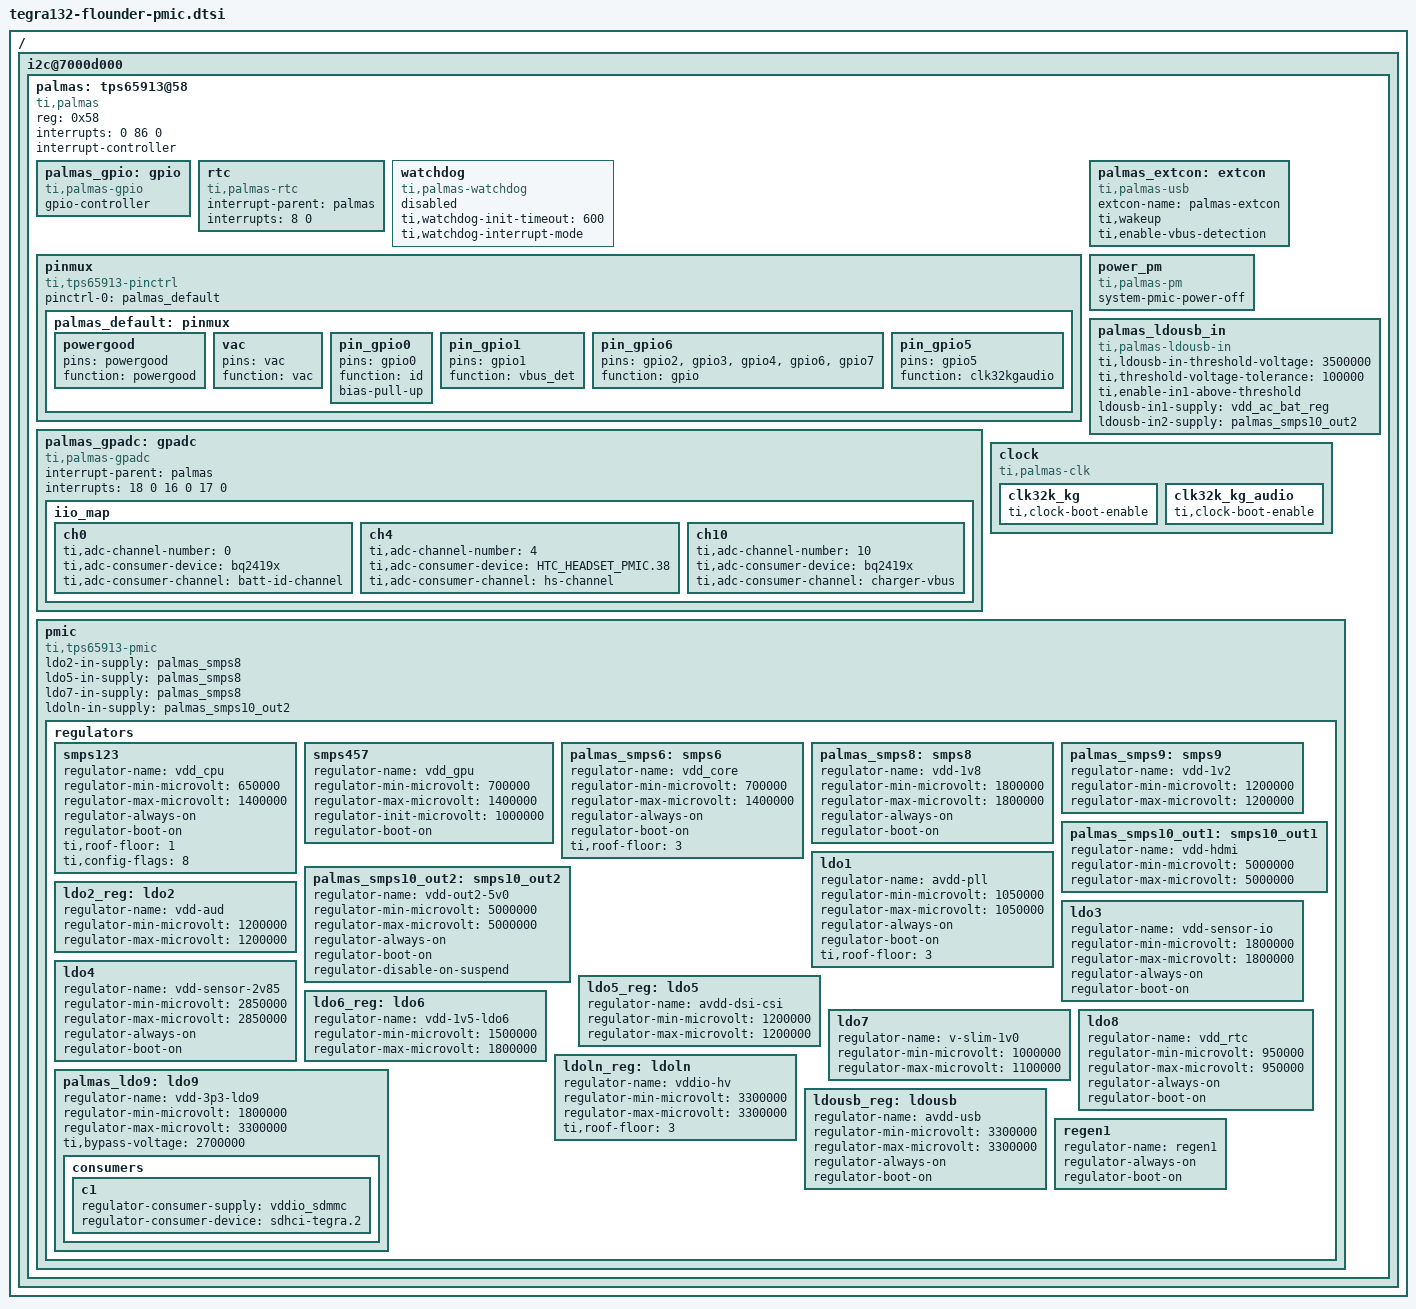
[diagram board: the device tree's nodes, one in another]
/*
 * Copyright (c) 2013-2015, NVIDIA CORPORATION.  All rights reserved.
 *
 * This program is free software; you can redistribute it and/or modify it
 * under the terms and conditions of the GNU General Public License,
 * version 2, as published by the Free Software Foundation.
 *
 * This program is distributed in the hope it will be useful, but WITHOUT
 * ANY WARRANTY; without even the implied warranty of MERCHANTABILITY or
 * FITNESS FOR A PARTICULAR PURPOSE.  See the GNU General Public License for
 * more details.
 *
 * You should have received a copy of the GNU General Public License
 * along with this program.  If not, see <http://www.gnu.org/licenses/>.
 */

#include <dt-bindings/gpio/tegra-gpio.h>
#include <dt-bindings/mfd/palmas.h>

/ {
	i2c@7000d000 {
		palmas: tps65913@58 {
			compatible = "ti,palmas";
			reg = <0x58>;
			interrupts = <0 86 0>;

			#interrupt-cells = <2>;
			interrupt-controller;

			palmas_gpio: gpio {
				compatible = "ti,palmas-gpio";
				gpio-controller;
				#gpio-cells = <2>;
			};

			rtc {
				compatible = "ti,palmas-rtc";
				interrupt-parent = <&palmas>;
				interrupts = <8 0>;
			};

			watchdog {
				compatible = "ti,palmas-watchdog";
				ti,watchdog-init-timeout = <600>;
				ti,watchdog-interrupt-mode;
				status = "disabled";
			};

			pinmux {
				compatible = "ti,tps65913-pinctrl";
				pinctrl-names = "default";
				pinctrl-0 = <&palmas_default>;

				palmas_default: pinmux {
					powergood {
						pins = "powergood";
						function = "powergood";
					};

					vac {
						pins = "vac";
						function = "vac";
					};

					pin_gpio0 {
						pins = "gpio0";
						function = "id";
						bias-pull-up;
					};

					pin_gpio1 {
						pins = "gpio1";
						function = "vbus_det";
					};

					pin_gpio6 {
						pins = "gpio2", "gpio3", "gpio4", "gpio6", "gpio7";
						function = "gpio";
					};

					pin_gpio5 {
						pins = "gpio5";
						function = "clk32kgaudio";
					};
				};
			};

			palmas_extcon: extcon {
				compatible = "ti,palmas-usb";
				extcon-name = "palmas-extcon";
				ti,wakeup;
				#extcon-cells = <1>;
				ti,enable-vbus-detection;
			};

			power_pm {
				compatible = "ti,palmas-pm";
				system-pmic-power-off;
			};

			palmas_ldousb_in {
				compatible = "ti,palmas-ldousb-in";
				ti,ldousb-in-threshold-voltage = <3500000>;
				ti,threshold-voltage-tolerance = <100000>;
				ti,enable-in1-above-threshold;
				ldousb-in1-supply = <&vdd_ac_bat_reg>;
				ldousb-in2-supply = <&palmas_smps10_out2>;
			};

			palmas_gpadc: gpadc {
				compatible = "ti,palmas-gpadc";
				interrupt-parent = <&palmas>;
				interrupts = <18 0
					      16 0
					      17 0>;
				iio_map {
					ch0 {
						ti,adc-channel-number = <0>;
						ti,adc-consumer-device = "bq2419x";
						ti,adc-consumer-channel = "batt-id-channel";
					};

					ch4 {
						ti,adc-channel-number = <4>;
						ti,adc-consumer-device = "HTC_HEADSET_PMIC.38";
						ti,adc-consumer-channel = "hs-channel";
					};

					ch10 {
						ti,adc-channel-number = <10>;
						ti,adc-consumer-device = "bq2419x";
						ti,adc-consumer-channel = "charger-vbus";
					};
				};

			};

			clock {
				compatible = "ti,palmas-clk";

				clk32k_kg {
					ti,clock-boot-enable;
				};

				clk32k_kg_audio {
					ti,clock-boot-enable;
				};
			};

			pmic {
				compatible = "ti,tps65913-pmic", "ti,palmas-pmic";
				ldo2-in-supply = <&palmas_smps8>;
				ldo5-in-supply = <&palmas_smps8>;
				ldo7-in-supply = <&palmas_smps8>;
				ldoln-in-supply = <&palmas_smps10_out2>;
			//	ldousb-in-supply = <&palmas_smps10_out2>;

				regulators {
					smps123 {
						regulator-name = "vdd_cpu";
						regulator-min-microvolt = <650000>;
						regulator-max-microvolt = <1400000>;
						regulator-always-on;
						regulator-boot-on;
						ti,roof-floor = <1>;
						ti,config-flags = <8>;
					};

					smps457 {
						regulator-name = "vdd_gpu";
						regulator-min-microvolt = <700000>;
						regulator-max-microvolt = <1400000>;
						regulator-init-microvolt = <1000000>;
						regulator-boot-on;
					};

					palmas_smps6: smps6 {
						regulator-name = "vdd_core";
						regulator-min-microvolt = <700000>;
						regulator-max-microvolt = <1400000>;
						regulator-always-on;
						regulator-boot-on;
						ti,roof-floor = <3>;
					};

					palmas_smps8: smps8 {
						regulator-name = "vdd-1v8";
						regulator-min-microvolt = <1800000>;
						regulator-max-microvolt = <1800000>;
						regulator-always-on;
						regulator-boot-on;

					};

					palmas_smps9: smps9 {
						regulator-name = "vdd-1v2";
						regulator-min-microvolt = <1200000>;
						regulator-max-microvolt = <1200000>;

					};

					palmas_smps10_out1: smps10_out1 {
						regulator-name = "vdd-hdmi";
						regulator-min-microvolt = <5000000>;
						regulator-max-microvolt = <5000000>;

					};

					palmas_smps10_out2: smps10_out2 {
						regulator-name = "vdd-out2-5v0";
						regulator-min-microvolt = <5000000>;
						regulator-max-microvolt = <5000000>;
						regulator-always-on;
						regulator-boot-on;
						regulator-disable-on-suspend;

					};

					ldo1 {
						regulator-name = "avdd-pll";
						regulator-min-microvolt = <1050000>;
						regulator-max-microvolt = <1050000>;
						regulator-always-on;
						regulator-boot-on;
						ti,roof-floor = <3>;

					};

					ldo2_reg: ldo2 {
						regulator-name = "vdd-aud";
						regulator-min-microvolt = <1200000>;
						regulator-max-microvolt = <1200000>;

					};

					ldo3 {
						regulator-name = "vdd-sensor-io";
						regulator-min-microvolt = <1800000>;
						regulator-max-microvolt = <1800000>;
						regulator-always-on;
						regulator-boot-on;

					};

					ldo4 {
						regulator-name = "vdd-sensor-2v85";
						regulator-min-microvolt = <2850000>;
						regulator-max-microvolt = <2850000>;
						regulator-always-on;
						regulator-boot-on;

					};

					ldo5_reg: ldo5 {
						regulator-name = "avdd-dsi-csi";
						regulator-min-microvolt = <1200000>;
						regulator-max-microvolt = <1200000>;
					};

					ldo6_reg: ldo6 {
						regulator-name = "vdd-1v5-ldo6";
						regulator-min-microvolt = <1500000>;
						regulator-max-microvolt = <1800000>;
					};

					ldo7 {
						regulator-name = "v-slim-1v0";
						regulator-min-microvolt = <1000000>;
						regulator-max-microvolt = <1100000>;

					};

					ldo8 {
						regulator-name = "vdd_rtc";
						regulator-min-microvolt = <950000>;
						regulator-max-microvolt = <950000>;
						regulator-always-on;
						regulator-boot-on;

					};

					palmas_ldo9: ldo9 {
						regulator-name = "vdd-3p3-ldo9";
						regulator-min-microvolt = <1800000>;
						regulator-max-microvolt = <3300000>;
						ti,bypass-voltage = <2700000>;

						consumers {
							c1 {
								regulator-consumer-supply = "vddio_sdmmc";
								regulator-consumer-device = "sdhci-tegra.2";
							};
						};
					};

					ldoln_reg: ldoln {
						regulator-name = "vddio-hv";
						regulator-min-microvolt = <3300000>;
						regulator-max-microvolt = <3300000>;
						ti,roof-floor = <3>;
					};

					ldousb_reg: ldousb {
						regulator-name = "avdd-usb";
						regulator-min-microvolt = <3300000>;
						regulator-max-microvolt = <3300000>;
						regulator-always-on;
						regulator-boot-on;
					};

					regen1 {
						regulator-name = "regen1";
						regulator-always-on;
						regulator-boot-on;
					};
				};
			};
		};
	};
};
